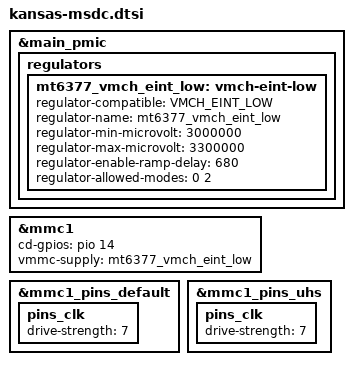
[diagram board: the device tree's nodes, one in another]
/* Copyright (c) 2024, Motorola Mobility Inc. All rights reserved.
 *
 * This program is free software; you can redistribute it and/or modify
 * it under the terms of the GNU General Public License version 2 and
 * only version 2 as published by the Free Software Foundation.
 *
 * This program is distributed in the hope that it will be useful,
 * but WITHOUT ANY WARRANTY; without even the implied warranty of
 * MERCHANTABILITY or FITNESS FOR A PARTICULAR PURPOSE.  See the
 * GNU General Public License for more details.
 */

/*[TN.NJDC] card overlay file.start*/
&main_pmic {
        regulators {
                mt6377_vmch_eint_low: vmch-eint-low  {
                        regulator-compatible = "VMCH_EINT_LOW";
                        regulator-name = "mt6377_vmch_eint_low";
                        regulator-min-microvolt = <3000000>;
                        regulator-max-microvolt = <3300000>;
                        regulator-enable-ramp-delay = <680>;
                        regulator-allowed-modes = <0 2>;
                };
        };
};

&mmc1 {
        cd-gpios = <&pio 14 GPIO_ACTIVE_HIGH>;
        vmmc-supply = <&mt6377_vmch_eint_low>;
};


&mmc1_pins_default {
        pins_clk {
                drive-strength = <7>;
        };
};

&mmc1_pins_uhs {
        pins_clk {
                drive-strength = <7>;
        };
};
/*[TN.NJDC] card overlay file.end*/
